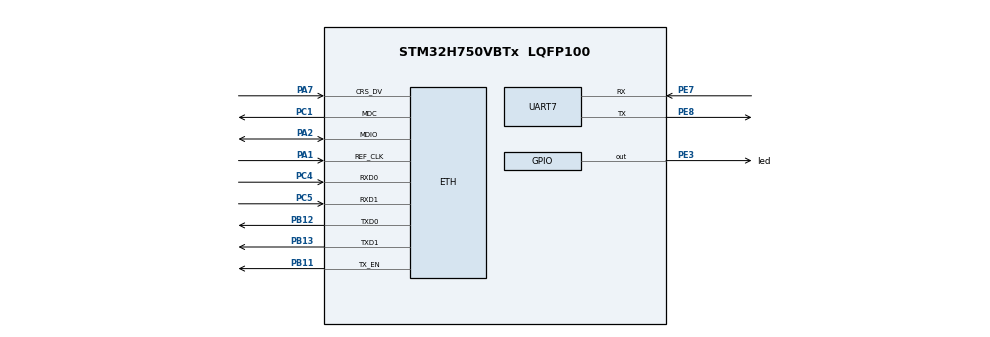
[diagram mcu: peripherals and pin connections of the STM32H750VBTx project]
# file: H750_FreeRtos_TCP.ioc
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CORTEX_M7.AccessPermission-Cortex_Memory_Protection_Unit_Region0_Settings=MPU_REGION_FULL_ACCESS
CORTEX_M7.AccessPermission-Cortex_Memory_Protection_Unit_Region1_Settings=MPU_REGION_FULL_ACCESS
CORTEX_M7.AccessPermission-Cortex_Memory_Protection_Unit_Region2_Settings=MPU_REGION_FULL_ACCESS
CORTEX_M7.BaseAddress-Cortex_Memory_Protection_Unit_Region0_Settings=0x30040000
CORTEX_M7.BaseAddress-Cortex_Memory_Protection_Unit_Region1_Settings=0x30044000
CORTEX_M7.BaseAddress-Cortex_Memory_Protection_Unit_Region2_Settings=0x24000000
CORTEX_M7.CPU_DCache=Enabled
CORTEX_M7.CPU_ICache=Enabled
CORTEX_M7.Enable-Cortex_Memory_Protection_Unit_Region0_Settings=MPU_REGION_ENABLE
CORTEX_M7.Enable-Cortex_Memory_Protection_Unit_Region1_Settings=MPU_REGION_ENABLE
CORTEX_M7.Enable-Cortex_Memory_Protection_Unit_Region2_Settings=MPU_REGION_ENABLE
CORTEX_M7.IsBufferable-Cortex_Memory_Protection_Unit_Region0_Settings=MPU_ACCESS_BUFFERABLE
CORTEX_M7.IsBufferable-Cortex_Memory_Protection_Unit_Region1_Settings=MPU_ACCESS_BUFFERABLE
CORTEX_M7.IsBufferable-Cortex_Memory_Protection_Unit_Region2_Settings=MPU_ACCESS_BUFFERABLE
CORTEX_M7.IsCacheable-Cortex_Memory_Protection_Unit_Region1_Settings=MPU_ACCESS_CACHEABLE
CORTEX_M7.IsCacheable-Cortex_Memory_Protection_Unit_Region2_Settings=MPU_ACCESS_CACHEABLE
CORTEX_M7.MPU_Control=MPU_PRIVILEGED_DEFAULT
CORTEX_M7.Size-Cortex_Memory_Protection_Unit_Region0_Settings=MPU_REGION_SIZE_256B
CORTEX_M7.Size-Cortex_Memory_Protection_Unit_Region1_Settings=MPU_REGION_SIZE_16KB
CORTEX_M7.Size-Cortex_Memory_Protection_Unit_Region2_Settings=MPU_REGION_SIZE_512KB
CORTEX_M7.TypeExtField-Cortex_Memory_Protection_Unit_Region2_Settings=MPU_TEX_LEVEL1
CORTEX_M7.default_mode_Activation=0
Dma.Request0=UART7_RX
Dma.Request1=UART7_TX
Dma.UART7_RX.0.Direction=DMA_PERIPH_TO_MEMORY
Dma.UART7_RX.0.EventEnable=DISABLE
Dma.UART7_RX.0.FIFOMode=DMA_FIFOMODE_DISABLE
Dma.UART7_RX.0.Instance=DMA1_Stream0
Dma.UART7_RX.0.MemDataAlignment=DMA_MDATAALIGN_BYTE
Dma.UART7_RX.0.MemInc=DMA_MINC_ENABLE
Dma.UART7_RX.0.Mode=DMA_NORMAL
Dma.UART7_RX.0.PeriphDataAlignment=DMA_PDATAALIGN_BYTE
Dma.UART7_RX.0.PeriphInc=DMA_PINC_DISABLE
Dma.UART7_RX.0.Polarity=HAL_DMAMUX_REQ_GEN_RISING
Dma.UART7_RX.0.Priority=DMA_PRIORITY_LOW
Dma.UART7_RX.0.RequestNumber=1
Dma.UART7_RX.0.SignalID=NONE
Dma.UART7_RX.0.SyncEnable=DISABLE
Dma.UART7_RX.0.SyncPolarity=HAL_DMAMUX_SYNC_NO_EVENT
Dma.UART7_RX.0.SyncRequestNumber=1
Dma.UART7_RX.0.SyncSignalID=NONE
Dma.UART7_TX.1.Direction=DMA_MEMORY_TO_PERIPH
Dma.UART7_TX.1.EventEnable=DISABLE
Dma.UART7_TX.1.FIFOMode=DMA_FIFOMODE_DISABLE
Dma.UART7_TX.1.Instance=DMA1_Stream1
Dma.UART7_TX.1.MemDataAlignment=DMA_MDATAALIGN_BYTE
Dma.UART7_TX.1.MemInc=DMA_MINC_ENABLE
Dma.UART7_TX.1.Mode=DMA_NORMAL
Dma.UART7_TX.1.PeriphDataAlignment=DMA_PDATAALIGN_BYTE
Dma.UART7_TX.1.PeriphInc=DMA_PINC_DISABLE
Dma.UART7_TX.1.Polarity=HAL_DMAMUX_REQ_GEN_RISING
Dma.UART7_TX.1.Priority=DMA_PRIORITY_LOW
Dma.UART7_TX.1.RequestNumber=1
Dma.UART7_TX.1.SignalID=NONE
Dma.UART7_TX.1.SyncEnable=DISABLE
Dma.UART7_TX.1.SyncPolarity=HAL_DMAMUX_SYNC_NO_EVENT
Dma.UART7_TX.1.SyncRequestNumber=1
Dma.UART7_TX.1.SyncSignalID=NONE
ETH.MediaInterface=HAL_ETH_RMII_MODE
ETH.RxBuffLen=1536
ETH.RxDescAddress=0x30040000
ETH.TxDescAddress=0x30040060
FREERTOS.Tasks01=defaultTask,0,128,StartDefaultTask,Default,NULL,Dynamic,NULL,NULL;myTask02,-3,1024,StartTask02,Default,NULL,Dynamic,NULL,NULL;myTask03,-3,4096,StartTask03,Default,NULL,Dynamic,NULL,NULL
FREERTOS.configTOTAL_HEAP_SIZE=65535
Mcu.Family=STM32H7
Mcu.Name=STM32H750VBTx
Mcu.Package=LQFP100
NVIC.DMA1_Stream0_IRQn=true\:5\:0\:false\:false\:true\:true\:false\:true\:true
NVIC.DMA1_Stream1_IRQn=true\:5\:0\:false\:false\:true\:true\:false\:true\:true
NVIC.ETH_IRQn=true\:5\:0\:false\:false\:true\:true\:true\:true\:true
NVIC.PriorityGroup=NVIC_PRIORITYGROUP_4
NVIC.TIM7_IRQn=true\:15\:0\:false\:false\:true\:false\:false\:true\:true
NVIC.TimeBase=TIM7_IRQn
NVIC.TimeBaseIP=TIM7
NVIC.UART7_IRQn=true\:5\:0\:false\:false\:true\:true\:true\:true\:true
PA1.Mode=RMII
PA1.Signal=ETH_REF_CLK
PA13\ (JTMS/SWDIO).Mode=Serial_Wire
PA13\ (JTMS/SWDIO).Signal=DEBUG_JTMS-SWDIO
PA14\ (JTCK/SWCLK).Mode=Serial_Wire
PA14\ (JTCK/SWCLK).Signal=DEBUG_JTCK-SWCLK
PA2.Mode=RMII
PA2.Signal=ETH_MDIO
PA7.Mode=RMII
PA7.Signal=ETH_CRS_DV
PB11.Mode=RMII
PB11.Signal=ETH_TX_EN
PB12.Mode=RMII
PB12.Signal=ETH_TXD0
PB13.Mode=RMII
PB13.Signal=ETH_TXD1
PC1.Mode=RMII
PC1.Signal=ETH_MDC
PC4.Mode=RMII
PC4.Signal=ETH_RXD0
PC5.Mode=RMII
PC5.Signal=ETH_RXD1
PE3.GPIO_Label=led
PE3.Signal=GPIO_Output
PE7.Mode=Asynchronous
PE7.Signal=UART7_RX
PE8.Mode=Asynchronous
PE8.Signal=UART7_TX
PH0-OSC_IN\ (PH0).Mode=HSE-External-Oscillator
PH0-OSC_IN\ (PH0).Signal=RCC_OSC_IN
PH1-OSC_OUT\ (PH1).Mode=HSE-External-Oscillator
PH1-OSC_OUT\ (PH1).Signal=RCC_OSC_OUT
ProjectManager.HeapSize=0x32000
ProjectManager.StackSize=0x1000
ProjectManager.TargetToolchain=MDK-ARM V5.32
RCC.ADCFreq_Value=252000000
RCC.APB1Freq_Value=120000000
RCC.APB2Freq_Value=120000000
RCC.APB3Freq_Value=120000000
RCC.APB4Freq_Value=120000000
RCC.CortexFreq_Value=480000000
RCC.D1PPRE=RCC_APB3_DIV2
RCC.D2PPRE1=RCC_APB1_DIV2
RCC.D2PPRE2=RCC_APB2_DIV2
RCC.D3PPRE=RCC_APB4_DIV2
RCC.DIVM1=5
RCC.DIVM2=25
RCC.DIVN1=192
RCC.DIVN2=504
RCC.DIVQ2=72
RCC.HCLKFreq_Value=240000000
RCC.HPRE=RCC_HCLK_DIV2
RCC.HSE_VALUE=25000000
RCC.PLL2FRACN=0
RCC.PLL3FRACN=0
RCC.PLLSourceVirtual=RCC_PLLSOURCE_HSE
RCC.ProductRev=revV
RCC.SYSCLKFreq_VALUE=480000000
RCC.SYSCLKSource=RCC_SYSCLKSOURCE_PLLCLK
RCC.USBFreq_Value=480000000
VP_FREERTOS_VS_CMSIS_V1.Mode=CMSIS_V1
VP_SYS_VS_tim7.Mode=TIM7
board=custom

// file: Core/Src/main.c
/* USER CODE BEGIN Header */
/**
  ******************************************************************************
  * @file           : main.c
  * @brief          : Main program body
  ******************************************************************************
  * @attention
  *
  * Copyright (c) 2023 STMicroelectronics.
  * All rights reserved.
  *
  * This software is licensed under terms that can be found in the LICENSE file
  * in the root directory of this software component.
  * If no LICENSE file comes with this software, it is provided AS-IS.
  *
  ******************************************************************************
  */
/* USER CODE END Header */
#include "main.h"
#include "cmsis_os.h"
#include "dma.h"
#include "eth.h"
#include "usart.h"
#include "gpio.h"

void SystemClock_Config(void);
static void MPU_Initialize(void);
static void MPU_Config(void);
void MX_FREERTOS_Init(void);

int main(void)
{

  /* Enable I-Cache---------------------------------------------------------*/
  SCB_EnableICache();

  /* Enable D-Cache---------------------------------------------------------*/
  SCB_EnableDCache();

  /* MCU Configuration--------------------------------------------------------*/

  /* Reset of all peripherals, Initializes the Flash interface and the Systick. */
  HAL_Init();

  /* MPU Configuration--------------------------------------------------------*/
  MPU_Config();

  /* Configure the system clock */
  SystemClock_Config();

  /* Initialize all configured peripherals */
  MX_GPIO_Init();
  MX_DMA_Init();
  MX_UART7_Init();
  MX_ETH_Init();

  /* Call init function for freertos objects (in freertos.c) */
  MX_FREERTOS_Init();

  /* Start scheduler */
  osKernelStart();

  /* We should never get here as control is now taken by the scheduler */
  /* Infinite loop */
  while (1)
  {

  }
}

void SystemClock_Config(void)
{
  RCC_OscInitTypeDef RCC_OscInitStruct = {0};
  RCC_ClkInitTypeDef RCC_ClkInitStruct = {0};

  /** Supply configuration update enable
  */
  HAL_PWREx_ConfigSupply(PWR_LDO_SUPPLY);

  /** Configure the main internal regulator output voltage
  */
  __HAL_PWR_VOLTAGESCALING_CONFIG(PWR_REGULATOR_VOLTAGE_SCALE1);

  while(!__HAL_PWR_GET_FLAG(PWR_FLAG_VOSRDY)) {}

  __HAL_RCC_SYSCFG_CLK_ENABLE();
  __HAL_PWR_VOLTAGESCALING_CONFIG(PWR_REGULATOR_VOLTAGE_SCALE0);

  while(!__HAL_PWR_GET_FLAG(PWR_FLAG_VOSRDY)) {}

  /** Initializes the RCC Oscillators according to the specified parameters
  * in the RCC_OscInitTypeDef structure.
  */
  RCC_OscInitStruct.OscillatorType = RCC_OSCILLATORTYPE_HSE;
  RCC_OscInitStruct.HSEState = RCC_HSE_ON;
  RCC_OscInitStruct.PLL.PLLState = RCC_PLL_ON;
  RCC_OscInitStruct.PLL.PLLSource = RCC_PLLSOURCE_HSE;
  RCC_OscInitStruct.PLL.PLLM = 5;
  RCC_OscInitStruct.PLL.PLLN = 192;
  RCC_OscInitStruct.PLL.PLLP = 2;
  RCC_OscInitStruct.PLL.PLLQ = 2;
  RCC_OscInitStruct.PLL.PLLR = 2;
  RCC_OscInitStruct.PLL.PLLRGE = RCC_PLL1VCIRANGE_2;
  RCC_OscInitStruct.PLL.PLLVCOSEL = RCC_PLL1VCOWIDE;
  RCC_OscInitStruct.PLL.PLLFRACN = 0;
  if (HAL_RCC_OscConfig(&RCC_OscInitStruct) != HAL_OK)
  {
    Error_Handler();
  }

  /** Initializes the CPU, AHB and APB buses clocks
  */
  RCC_ClkInitStruct.ClockType = RCC_CLOCKTYPE_HCLK|RCC_CLOCKTYPE_SYSCLK
                              |RCC_CLOCKTYPE_PCLK1|RCC_CLOCKTYPE_PCLK2
                              |RCC_CLOCKTYPE_D3PCLK1|RCC_CLOCKTYPE_D1PCLK1;
  RCC_ClkInitStruct.SYSCLKSource = RCC_SYSCLKSOURCE_PLLCLK;
  RCC_ClkInitStruct.SYSCLKDivider = RCC_SYSCLK_DIV1;
  RCC_ClkInitStruct.AHBCLKDivider = RCC_HCLK_DIV2;
  RCC_ClkInitStruct.APB3CLKDivider = RCC_APB3_DIV2;
  RCC_ClkInitStruct.APB1CLKDivider = RCC_APB1_DIV2;
  RCC_ClkInitStruct.APB2CLKDivider = RCC_APB2_DIV2;
  RCC_ClkInitStruct.APB4CLKDivider = RCC_APB4_DIV2;

  if (HAL_RCC_ClockConfig(&RCC_ClkInitStruct, FLASH_LATENCY_4) != HAL_OK)
  {
    Error_Handler();
  }
}

/* MPU Configuration */

void MPU_Config(void)
{
  MPU_Region_InitTypeDef MPU_InitStruct = {0};

  /* Disables the MPU */
  HAL_MPU_Disable();

  /** Initializes and configures the Region and the memory to be protected
  */
  MPU_InitStruct.Enable = MPU_REGION_ENABLE;
  MPU_InitStruct.Number = MPU_REGION_NUMBER0;
  MPU_InitStruct.BaseAddress = 0x30040000;
  MPU_InitStruct.Size = MPU_REGION_SIZE_256B;
  MPU_InitStruct.SubRegionDisable = 0x0;
  MPU_InitStruct.TypeExtField = MPU_TEX_LEVEL0;
  MPU_InitStruct.AccessPermission = MPU_REGION_FULL_ACCESS;
  MPU_InitStruct.DisableExec = MPU_INSTRUCTION_ACCESS_ENABLE;
  MPU_InitStruct.IsShareable = MPU_ACCESS_NOT_SHAREABLE;
  MPU_InitStruct.IsCacheable = MPU_ACCESS_NOT_CACHEABLE;
  MPU_InitStruct.IsBufferable = MPU_ACCESS_BUFFERABLE;

  HAL_MPU_ConfigRegion(&MPU_InitStruct);

  /** Initializes and configures the Region and the memory to be protected
  */
  MPU_InitStruct.Number = MPU_REGION_NUMBER1;
  MPU_InitStruct.BaseAddress = 0x30044000;
  MPU_InitStruct.Size = MPU_REGION_SIZE_16KB;
  MPU_InitStruct.IsCacheable = MPU_ACCESS_CACHEABLE;

  HAL_MPU_ConfigRegion(&MPU_InitStruct);

  /** Initializes and configures the Region and the memory to be protected
  */
  MPU_InitStruct.Number = MPU_REGION_NUMBER2;
  MPU_InitStruct.BaseAddress = 0x24000000;
  MPU_InitStruct.Size = MPU_REGION_SIZE_512KB;
  MPU_InitStruct.TypeExtField = MPU_TEX_LEVEL1;

  HAL_MPU_ConfigRegion(&MPU_InitStruct);
  /* Enables the MPU */
  HAL_MPU_Enable(MPU_PRIVILEGED_DEFAULT);

}

void HAL_TIM_PeriodElapsedCallback(TIM_HandleTypeDef *htim)
{
  if (htim->Instance == TIM7) {
    HAL_IncTick();
  }
}

void Error_Handler(void)
{
  __disable_irq();
  while (1)
  {
  }
}

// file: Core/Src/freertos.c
/* USER CODE BEGIN Header */
/**
  ******************************************************************************
  * File Name          : freertos.c
  * Description        : Code for freertos applications
  ******************************************************************************
  * @attention
  *
  * Copyright (c) 2023 STMicroelectronics.
  * All rights reserved.
  *
  * This software is licensed under terms that can be found in the LICENSE file
  * in the root directory of this software component.
  * If no LICENSE file comes with this software, it is provided AS-IS.
  *
  ******************************************************************************
  */
/* USER CODE END Header */

#include "FreeRTOS.h"
#include "task.h"
#include "main.h"
#include "cmsis_os.h"

osThreadId defaultTaskHandle;
osThreadId myTask02Handle;
osThreadId myTask03Handle;

void StartDefaultTask(void const * argument);
void StartTask02(void const * argument);
void StartTask03(void const * argument);

void MX_FREERTOS_Init(void); /* (MISRA C 2004 rule 8.1) */

/* GetIdleTaskMemory prototype (linked to static allocation support) */
void vApplicationGetIdleTaskMemory( StaticTask_t **ppxIdleTaskTCBBuffer, StackType_t **ppxIdleTaskStackBuffer, uint32_t *pulIdleTaskStackSize );

/* USER CODE BEGIN GET_IDLE_TASK_MEMORY */
static StaticTask_t xIdleTaskTCBBuffer;
static StackType_t xIdleStack[configMINIMAL_STACK_SIZE];

void vApplicationGetIdleTaskMemory( StaticTask_t **ppxIdleTaskTCBBuffer, StackType_t **ppxIdleTaskStackBuffer, uint32_t *pulIdleTaskStackSize )
{
  *ppxIdleTaskTCBBuffer = &xIdleTaskTCBBuffer;
  *ppxIdleTaskStackBuffer = &xIdleStack[0];
  *pulIdleTaskStackSize = configMINIMAL_STACK_SIZE;
  /* place for user code */
}
/* USER CODE END GET_IDLE_TASK_MEMORY */

void MX_FREERTOS_Init(void) {

  /* Create the thread(s) */
  /* definition and creation of defaultTask */
  osThreadDef(defaultTask, StartDefaultTask, osPriorityNormal, 0, 128);
  defaultTaskHandle = osThreadCreate(osThread(defaultTask), NULL);

  /* definition and creation of myTask02 */
  osThreadDef(myTask02, StartTask02, osPriorityIdle, 0, 1024);
  myTask02Handle = osThreadCreate(osThread(myTask02), NULL);

  /* definition and creation of myTask03 */
  osThreadDef(myTask03, StartTask03, osPriorityIdle, 0, 4096);
  myTask03Handle = osThreadCreate(osThread(myTask03), NULL);

}

void StartDefaultTask(void const * argument)
{
  /* USER CODE BEGIN StartDefaultTask */
  /* Infinite loop */
  for(;;)
  {
      led_GPIO_Port->ODR^=led_Pin;
    osDelay(100);
  }
  /* USER CODE END StartDefaultTask */
}

void StartTask02(void const * argument)
{
  for(;;)
  {
    osDelay(1);
  }
}

void StartTask03(void const * argument)
{
  for(;;)
  {
    osDelay(1);
  }
}
